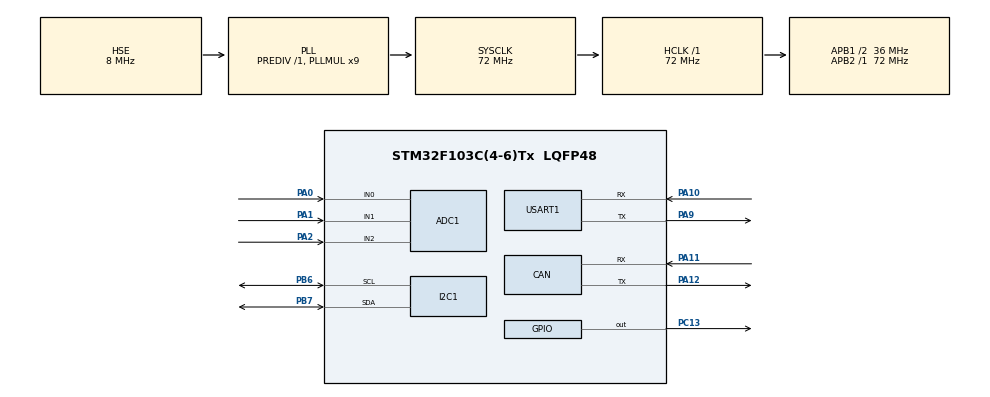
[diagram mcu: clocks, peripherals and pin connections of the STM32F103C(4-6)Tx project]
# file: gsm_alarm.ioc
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ADC1.Channel-0\#ChannelRegularConversion=ADC_CHANNEL_0
ADC1.NbrOfConversionFlag=1
ADC1.Rank-0\#ChannelRegularConversion=1
ADC1.SamplingTime-0\#ChannelRegularConversion=ADC_SAMPLETIME_1CYCLE_5
ADC1.master=1
CAN.CalculateTimeBit=1333
CAN.CalculateTimeQuantum=444.44444444444446
Mcu.Family=STM32F1
Mcu.Name=STM32F103C(4-6)Tx
Mcu.Package=LQFP48
NVIC.I2C1_EV_IRQn=true\:0\:0\:false\:false\:true\:true
NVIC.PriorityGroup=NVIC_PRIORITYGROUP_4
NVIC.TIM1_UP_IRQn=true\:0\:0\:false\:false\:true\:true
NVIC.USART1_IRQn=true\:0\:0\:false\:false\:true\:true
PA0-WKUP.Signal=ADCx_IN0
PA1.Signal=ADCx_IN1
PA10.Mode=Asynchronous
PA10.Signal=USART1_RX
PA11.Mode=Master
PA11.Signal=CAN_RX
PA12.Mode=Master
PA12.Signal=CAN_TX
PA13.Mode=JTAG_4_pins
PA13.Signal=SYS_JTMS-SWDIO
PA14.Mode=JTAG_4_pins
PA14.Signal=SYS_JTCK-SWCLK
PA15.Mode=JTAG_4_pins
PA15.Signal=SYS_JTDI
PA2.Signal=ADCx_IN2
PA9.Mode=Asynchronous
PA9.Signal=USART1_TX
PB3.Mode=JTAG_4_pins
PB3.Signal=SYS_JTDO-TRACESWO
PB6.Mode=I2C
PB6.Signal=I2C1_SCL
PB7.Mode=I2C
PB7.Signal=I2C1_SDA
PC13-TAMPER-RTC.Signal=GPIO_Output
PC14-OSC32_IN.Mode=LSE-External-Oscillator
PC14-OSC32_IN.Signal=RCC_OSC32_IN
PC15-OSC32_OUT.Mode=LSE-External-Oscillator
PC15-OSC32_OUT.Signal=RCC_OSC32_OUT
PD0-OSC_IN.Mode=HSE-External-Oscillator
PD0-OSC_IN.Signal=RCC_OSC_IN
PD1-OSC_OUT.Mode=HSE-External-Oscillator
PD1-OSC_OUT.Signal=RCC_OSC_OUT
ProjectManager.HeapSize=0x200
ProjectManager.StackSize=0x400
ProjectManager.TargetToolchain=MDK-ARM V5
RCC.ADCPresc=RCC_ADCPCLK2_DIV6
RCC.AHBFreq_Value=72000000
RCC.APB1CLKDivider=RCC_HCLK_DIV2
RCC.APB1Freq_Value=36000000
RCC.APB1TimFreq_Value=72000000
RCC.APB2Freq_Value=72000000
RCC.APB2TimFreq_Value=72000000
RCC.HCLKFreq_Value=72000000
RCC.PLLMUL=RCC_PLL_MUL9
RCC.PLLSourceVirtual=RCC_PLLSOURCE_HSE
RCC.SYSCLKFreq_VALUE=72000000
RCC.SYSCLKSource=RCC_SYSCLKSOURCE_PLLCLK
RCC.USBFreq_Value=72000000
SH.ADCx_IN0.0=ADC1_IN0,IN0
SH.ADCx_IN1.0=ADC1_IN1,IN1
SH.ADCx_IN2.0=ADC1_IN2,IN2
TIM1.Prescaler=71
USART1.VirtualMode=VM_ASYNC
VP_RTC_VS_RTC_Activate.Mode=RTC_Enabled
VP_TIM1_VS_ClockSourceITR.Mode=TriggerSource_ITR0
VP_TIM1_VS_ControllerModeClock.Mode=Clock Mode
board=gsm_alarm

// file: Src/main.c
/**
  ******************************************************************************
  * File Name          : main.c
  * Description        : Main program body
  ******************************************************************************
  ** This notice applies to any and all portions of this file
  * that are not between comment pairs USER CODE BEGIN and
  * USER CODE END. Other portions of this file, whether
  * inserted by the user or by software development tools
  * are owned by their respective copyright owners.
  *
  * COPYRIGHT(c) 2024 STMicroelectronics
  *
  * Redistribution and use in source and binary forms, with or without modification,
  * are permitted provided that the following conditions are met:
  *   1. Redistributions of source code must retain the above copyright notice,
  *      this list of conditions and the following disclaimer.
  *   2. Redistributions in binary form must reproduce the above copyright notice,
  *      this list of conditions and the following disclaimer in the documentation
  *      and/or other materials provided with the distribution.
  *   3. Neither the name of STMicroelectronics nor the names of its contributors
  *      may be used to endorse or promote products derived from this software
  *      without specific prior written permission.
  *
  * THIS SOFTWARE IS PROVIDED BY THE COPYRIGHT HOLDERS AND CONTRIBUTORS "AS IS"
  * AND ANY EXPRESS OR IMPLIED WARRANTIES, INCLUDING, BUT NOT LIMITED TO, THE
  * IMPLIED WARRANTIES OF MERCHANTABILITY AND FITNESS FOR A PARTICULAR PURPOSE ARE
  * DISCLAIMED. IN NO EVENT SHALL THE COPYRIGHT HOLDER OR CONTRIBUTORS BE LIABLE
  * FOR ANY DIRECT, INDIRECT, INCIDENTAL, SPECIAL, EXEMPLARY, OR CONSEQUENTIAL
  * DAMAGES (INCLUDING, BUT NOT LIMITED TO, PROCUREMENT OF SUBSTITUTE GOODS OR
  * SERVICES; LOSS OF USE, DATA, OR PROFITS; OR BUSINESS INTERRUPTION) HOWEVER
  * CAUSED AND ON ANY THEORY OF LIABILITY, WHETHER IN CONTRACT, STRICT LIABILITY,
  * OR TORT (INCLUDING NEGLIGENCE OR OTHERWISE) ARISING IN ANY WAY OUT OF THE USE
  * OF THIS SOFTWARE, EVEN IF ADVISED OF THE POSSIBILITY OF SUCH DAMAGE.
  *
  ******************************************************************************
  */

#include "main.h"
#include "stm32f1xx_hal.h"
#include "SIM800A.h"

ADC_HandleTypeDef hadc1;

CAN_HandleTypeDef hcan;

I2C_HandleTypeDef hi2c1;

RTC_HandleTypeDef hrtc;

TIM_HandleTypeDef htim1;

UART_HandleTypeDef huart1;

/* USER CODE BEGIN PV */
/* Private variables ---------------------------------------------------------*/

/* USER CODE END PV */

void SystemClock_Config(void);
static void MX_GPIO_Init(void);
static void MX_CAN_Init(void);
static void MX_ADC1_Init(void);
static void MX_I2C1_Init(void);
static void MX_RTC_Init(void);
static void MX_TIM1_Init(void);
static void MX_USART1_UART_Init(void);

/* USER CODE BEGIN PFP */
/* Private function prototypes -----------------------------------------------*/

/* USER CODE END PFP */

int main(void)
{

  /* MCU Configuration----------------------------------------------------------*/

  /* Reset of all peripherals, Initializes the Flash interface and the Systick. */
  HAL_Init();

  /* Configure the system clock */
  SystemClock_Config();

  /* Initialize all configured peripherals */
  MX_GPIO_Init();
  MX_CAN_Init();
  MX_ADC1_Init();
  MX_I2C1_Init();
  MX_RTC_Init();
  MX_TIM1_Init();
  MX_USART1_UART_Init();

  /* Infinite loop */
  while (1)
  {

  /* USER CODE BEGIN 3 */
		HAL_GPIO_WritePin(GPIOC,GPIO_PIN_13,1);
		HAL_Delay(200);
		HAL_GPIO_WritePin(GPIOC,GPIO_PIN_13,0);
		HAL_Delay(200);
  }
  /* USER CODE END 3 */

}

/** System Clock Configuration
*/
void SystemClock_Config(void)
{

  RCC_OscInitTypeDef RCC_OscInitStruct;
  RCC_ClkInitTypeDef RCC_ClkInitStruct;
  RCC_PeriphCLKInitTypeDef PeriphClkInit;

    /**Initializes the CPU, AHB and APB busses clocks
    */
  RCC_OscInitStruct.OscillatorType = RCC_OSCILLATORTYPE_LSI|RCC_OSCILLATORTYPE_HSE;
  RCC_OscInitStruct.HSEState = RCC_HSE_ON;
  RCC_OscInitStruct.HSEPredivValue = RCC_HSE_PREDIV_DIV1;
  RCC_OscInitStruct.HSIState = RCC_HSI_ON;
  RCC_OscInitStruct.LSIState = RCC_LSI_ON;
  RCC_OscInitStruct.PLL.PLLState = RCC_PLL_ON;
  RCC_OscInitStruct.PLL.PLLSource = RCC_PLLSOURCE_HSE;
  RCC_OscInitStruct.PLL.PLLMUL = RCC_PLL_MUL9;
  if (HAL_RCC_OscConfig(&RCC_OscInitStruct) != HAL_OK)
  {
    _Error_Handler(__FILE__, __LINE__);
  }

    /**Initializes the CPU, AHB and APB busses clocks
    */
  RCC_ClkInitStruct.ClockType = RCC_CLOCKTYPE_HCLK|RCC_CLOCKTYPE_SYSCLK
                              |RCC_CLOCKTYPE_PCLK1|RCC_CLOCKTYPE_PCLK2;
  RCC_ClkInitStruct.SYSCLKSource = RCC_SYSCLKSOURCE_PLLCLK;
  RCC_ClkInitStruct.AHBCLKDivider = RCC_SYSCLK_DIV1;
  RCC_ClkInitStruct.APB1CLKDivider = RCC_HCLK_DIV2;
  RCC_ClkInitStruct.APB2CLKDivider = RCC_HCLK_DIV1;

  if (HAL_RCC_ClockConfig(&RCC_ClkInitStruct, FLASH_LATENCY_2) != HAL_OK)
  {
    _Error_Handler(__FILE__, __LINE__);
  }

  PeriphClkInit.PeriphClockSelection = RCC_PERIPHCLK_RTC|RCC_PERIPHCLK_ADC;
  PeriphClkInit.RTCClockSelection = RCC_RTCCLKSOURCE_LSI;
  PeriphClkInit.AdcClockSelection = RCC_ADCPCLK2_DIV6;
  if (HAL_RCCEx_PeriphCLKConfig(&PeriphClkInit) != HAL_OK)
  {
    _Error_Handler(__FILE__, __LINE__);
  }

    /**Configure the Systick interrupt time
    */
  HAL_SYSTICK_Config(HAL_RCC_GetHCLKFreq()/1000);

    /**Configure the Systick
    */
  HAL_SYSTICK_CLKSourceConfig(SYSTICK_CLKSOURCE_HCLK);

  /* SysTick_IRQn interrupt configuration */
  HAL_NVIC_SetPriority(SysTick_IRQn, 0, 0);
}

/* ADC1 init function */
static void MX_ADC1_Init(void)
{

  ADC_ChannelConfTypeDef sConfig;

    /**Common config
    */
  hadc1.Instance = ADC1;
  hadc1.Init.ScanConvMode = ADC_SCAN_DISABLE;
  hadc1.Init.ContinuousConvMode = DISABLE;
  hadc1.Init.DiscontinuousConvMode = DISABLE;
  hadc1.Init.ExternalTrigConv = ADC_SOFTWARE_START;
  hadc1.Init.DataAlign = ADC_DATAALIGN_RIGHT;
  hadc1.Init.NbrOfConversion = 1;
  if (HAL_ADC_Init(&hadc1) != HAL_OK)
  {
    _Error_Handler(__FILE__, __LINE__);
  }

    /**Configure Regular Channel
    */
  sConfig.Channel = ADC_CHANNEL_0;
  sConfig.Rank = 1;
  sConfig.SamplingTime = ADC_SAMPLETIME_1CYCLE_5;
  if (HAL_ADC_ConfigChannel(&hadc1, &sConfig) != HAL_OK)
  {
    _Error_Handler(__FILE__, __LINE__);
  }

}

/* CAN init function */
static void MX_CAN_Init(void)
{

  hcan.Instance = CAN1;
  hcan.Init.Prescaler = 16;
  hcan.Init.Mode = CAN_MODE_NORMAL;
  hcan.Init.SJW = CAN_SJW_1TQ;
  hcan.Init.BS1 = CAN_BS1_1TQ;
  hcan.Init.BS2 = CAN_BS2_1TQ;
  hcan.Init.TTCM = DISABLE;
  hcan.Init.ABOM = DISABLE;
  hcan.Init.AWUM = DISABLE;
  hcan.Init.NART = DISABLE;
  hcan.Init.RFLM = DISABLE;
  hcan.Init.TXFP = DISABLE;
  if (HAL_CAN_Init(&hcan) != HAL_OK)
  {
    _Error_Handler(__FILE__, __LINE__);
  }

}

/* I2C1 init function */
static void MX_I2C1_Init(void)
{

  hi2c1.Instance = I2C1;
  hi2c1.Init.ClockSpeed = 100000;
  hi2c1.Init.DutyCycle = I2C_DUTYCYCLE_2;
  hi2c1.Init.OwnAddress1 = 0;
  hi2c1.Init.AddressingMode = I2C_ADDRESSINGMODE_7BIT;
  hi2c1.Init.DualAddressMode = I2C_DUALADDRESS_DISABLE;
  hi2c1.Init.OwnAddress2 = 0;
  hi2c1.Init.GeneralCallMode = I2C_GENERALCALL_DISABLE;
  hi2c1.Init.NoStretchMode = I2C_NOSTRETCH_DISABLE;
  if (HAL_I2C_Init(&hi2c1) != HAL_OK)
  {
    _Error_Handler(__FILE__, __LINE__);
  }

}

/* RTC init function */
static void MX_RTC_Init(void)
{

    /**Initialize RTC Only
    */
  hrtc.Instance = RTC;
  hrtc.Init.AsynchPrediv = RTC_AUTO_1_SECOND;
  hrtc.Init.OutPut = RTC_OUTPUTSOURCE_ALARM;
  if (HAL_RTC_Init(&hrtc) != HAL_OK)
  {
    _Error_Handler(__FILE__, __LINE__);
  }

}

/* TIM1 init function */
static void MX_TIM1_Init(void)
{

  TIM_SlaveConfigTypeDef sSlaveConfig;
  TIM_MasterConfigTypeDef sMasterConfig;

  htim1.Instance = TIM1;
  htim1.Init.Prescaler = 71;
  htim1.Init.CounterMode = TIM_COUNTERMODE_UP;
  htim1.Init.Period = 0;
  htim1.Init.ClockDivision = TIM_CLOCKDIVISION_DIV1;
  htim1.Init.RepetitionCounter = 0;
  htim1.Init.AutoReloadPreload = TIM_AUTORELOAD_PRELOAD_DISABLE;
  if (HAL_TIM_Base_Init(&htim1) != HAL_OK)
  {
    _Error_Handler(__FILE__, __LINE__);
  }

  sSlaveConfig.SlaveMode = TIM_SLAVEMODE_EXTERNAL1;
  sSlaveConfig.InputTrigger = TIM_TS_ITR0;
  if (HAL_TIM_SlaveConfigSynchronization(&htim1, &sSlaveConfig) != HAL_OK)
  {
    _Error_Handler(__FILE__, __LINE__);
  }

  sMasterConfig.MasterOutputTrigger = TIM_TRGO_RESET;
  sMasterConfig.MasterSlaveMode = TIM_MASTERSLAVEMODE_DISABLE;
  if (HAL_TIMEx_MasterConfigSynchronization(&htim1, &sMasterConfig) != HAL_OK)
  {
    _Error_Handler(__FILE__, __LINE__);
  }

}

/* USART1 init function */
static void MX_USART1_UART_Init(void)
{

  huart1.Instance = USART1;
  huart1.Init.BaudRate = 115200;
  huart1.Init.WordLength = UART_WORDLENGTH_8B;
  huart1.Init.StopBits = UART_STOPBITS_1;
  huart1.Init.Parity = UART_PARITY_NONE;
  huart1.Init.Mode = UART_MODE_TX_RX;
  huart1.Init.HwFlowCtl = UART_HWCONTROL_NONE;
  huart1.Init.OverSampling = UART_OVERSAMPLING_16;
  if (HAL_UART_Init(&huart1) != HAL_OK)
  {
    _Error_Handler(__FILE__, __LINE__);
  }

}

/** Configure pins as
        * Analog
        * Input
        * Output
        * EVENT_OUT
        * EXTI
*/
static void MX_GPIO_Init(void)
{

  GPIO_InitTypeDef GPIO_InitStruct;

  /* GPIO Ports Clock Enable */
  __HAL_RCC_GPIOC_CLK_ENABLE();
  __HAL_RCC_GPIOD_CLK_ENABLE();
  __HAL_RCC_GPIOA_CLK_ENABLE();
  __HAL_RCC_GPIOB_CLK_ENABLE();

  /*Configure GPIO pin Output Level */
  HAL_GPIO_WritePin(GPIOC, GPIO_PIN_13, GPIO_PIN_RESET);

  /*Configure GPIO pin : PC13 */
  GPIO_InitStruct.Pin = GPIO_PIN_13;
  GPIO_InitStruct.Mode = GPIO_MODE_OUTPUT_PP;
  GPIO_InitStruct.Speed = GPIO_SPEED_FREQ_LOW;
  HAL_GPIO_Init(GPIOC, &GPIO_InitStruct);

}

void _Error_Handler(char * file, int line)
{
  while(1)
  {
  }
}

/************************ (C) COPYRIGHT STMicroelectronics *****END OF FILE****/
